# CC3200 register map
Vendor: Texas Instruments; File version: 1.0
CPU: CM4 r2p1, little endian, no MPU, no FPU, 3 interrupt priority bits
Registers are 32-bit, read-write, reset 0x0 unless marked. A register's access mark holds for its fields unless they carry their own. Offsets are from the block's base; [hi:lo] are bit positions; 'fields as' and 'values as' point back to an identical list.

## OCP_SHARED — MCU Shared Configuration
Base 0x4402E000
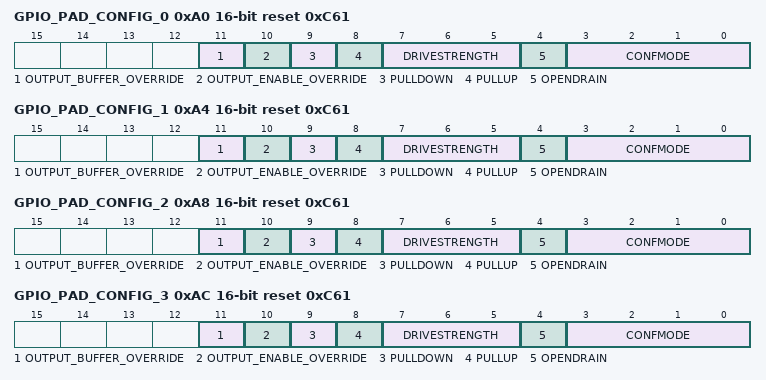
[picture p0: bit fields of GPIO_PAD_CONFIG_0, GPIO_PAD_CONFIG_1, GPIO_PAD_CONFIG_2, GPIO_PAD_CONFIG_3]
0xA0 GPIO_PAD_CONFIG_0 16-bit reset 0xC61 — GPIO0 / (ANA) (Pin 50) Pad Config
  [11] OUTPUT_BUFFER_OVERRIDE — Pad output buffer override enable
  [10] OUTPUT_ENABLE_OVERRIDE — Pad output enable override value
  [9] PULLDOWN — Enable internal weak pulldown
  [8] PULLUP — Enable internal weak pullup
  [7:5] DRIVESTRENGTH
    0=Disabled (Output driver not enabled); 1=2mA; 2=4mA; 3=6mA; 4=8mA; 5=10mA; 6=12mA; 7=14mA
  [4] OPENDRAIN — Open-drain Mode
  [3:0] CONFMODE — Configuration Mode
    0=GPIO0 (General-Purpose I/O); 3=UART0_RTS (UART0 Request To Send O (Active Low)); 4=McAXR0 (I2S Audio Port Data 0 (RX/TX)); 6=McAXR1 (I2S Audio Port Data 1 (RX/TX)); 7=GT_CCP00 (Timer Capture Port); 9=GSPI_CS (General SPI Chip Select); 10=UART1_RTS (UART1 Request To Send O (Active Low)); 12=UART0_CTS (UART0 Clear To Send Input (Active Low))
0xA4 GPIO_PAD_CONFIG_1 16-bit reset 0xC61 — GPIO1 (Pin 55) Pad Config
  [11] OUTPUT_BUFFER_OVERRIDE — Pad output buffer override enable
  [10] OUTPUT_ENABLE_OVERRIDE — Pad output enable override value
  [9] PULLDOWN — Enable internal weak pulldown
  [8] PULLUP — Enable internal weak pullup
  [7:5] DRIVESTRENGTH
    values as GPIO_PAD_CONFIG_0.DRIVESTRENGTH
  [4] OPENDRAIN — Open-drain Mode
  [3:0] CONFMODE — Configuration Mode
    0=GPIO1 (General-Purpose I/O); 3=UART0_TX (UART0 TX Data); 4=PIXCLK (Pixel Clock from Parallel Camera Sensor); 6=UART1_TX (UART1 TX Data); 7=GT_CCP01 (Timer Capture Port)
0xA8 GPIO_PAD_CONFIG_2 16-bit reset 0xC61 — GPIO2 (Pin 57) Pad Config
  [11] OUTPUT_BUFFER_OVERRIDE — Pad output buffer override enable
  [10] OUTPUT_ENABLE_OVERRIDE — Pad output enable override value
  [9] PULLDOWN — Enable internal weak pulldown
  [8] PULLUP — Enable internal weak pullup
  [7:5] DRIVESTRENGTH
    values as GPIO_PAD_CONFIG_0.DRIVESTRENGTH
  [4] OPENDRAIN — Open-drain Mode
  [3:0] CONFMODE — Configuration Mode
    0=GPIO2 (General-Purpose I/O); 3=UART0_RX (UART0 RX Data); 6=UART1_RX (UART1 RX Data); 7=GT_CCP02 (Timer Capture Port)
0xAC GPIO_PAD_CONFIG_3 16-bit reset 0xC61 — GPIO3 (Pin 58) Pad Config
  [11] OUTPUT_BUFFER_OVERRIDE — Pad output buffer override enable
  [10] OUTPUT_ENABLE_OVERRIDE — Pad output enable override value
  [9] PULLDOWN — Enable internal weak pulldown
  [8] PULLUP — Enable internal weak pullup
  [7:5] DRIVESTRENGTH
    values as GPIO_PAD_CONFIG_0.DRIVESTRENGTH
  [4] OPENDRAIN — Open-drain Mode
  [3:0] CONFMODE — Configuration Mode
    0=GPIO3 (General-Purpose I/O); 4=CAM_D3 (Parallel Camera Data Bit 3); 6=UART1_TX (UART1 TX Data)
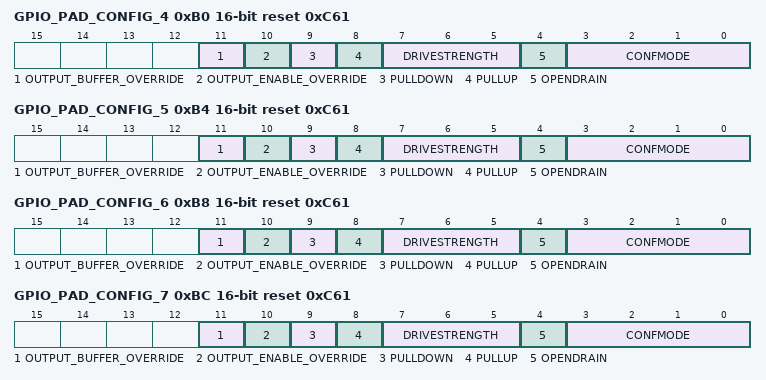
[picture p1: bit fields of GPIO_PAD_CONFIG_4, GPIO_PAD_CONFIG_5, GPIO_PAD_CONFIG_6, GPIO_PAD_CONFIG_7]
0xB0 GPIO_PAD_CONFIG_4 16-bit reset 0xC61 — GPIO4 (Pin 59) Pad Config
  [11] OUTPUT_BUFFER_OVERRIDE — Pad output buffer override enable
  [10] OUTPUT_ENABLE_OVERRIDE — Pad output enable override value
  [9] PULLDOWN — Enable internal weak pulldown
  [8] PULLUP — Enable internal weak pullup
  [7:5] DRIVESTRENGTH
    values as GPIO_PAD_CONFIG_0.DRIVESTRENGTH
  [4] OPENDRAIN — Open-drain Mode
  [3:0] CONFMODE — Configuration Mode
    0=GPIO4 (General-Purpose I/O); 4=CAM_D2 (Parallel Camera Data Bit 2); 6=UART1_RX (UART1 RX Data)
0xB4 GPIO_PAD_CONFIG_5 16-bit reset 0xC61 — GPIO5 (Pin 60) Pad Config
  [11] OUTPUT_BUFFER_OVERRIDE — Pad output buffer override enable
  [10] OUTPUT_ENABLE_OVERRIDE — Pad output enable override value
  [9] PULLDOWN — Enable internal weak pulldown
  [8] PULLUP — Enable internal weak pullup
  [7:5] DRIVESTRENGTH
    values as GPIO_PAD_CONFIG_0.DRIVESTRENGTH
  [4] OPENDRAIN — Open-drain Mode
  [3:0] CONFMODE — Configuration Mode
    0=GPIO5 (General-Purpose I/O); 4=CAM_D1 (Parallel Camera Data Bit 1); 6=McAXR1 (I2S Audio Port Data 1 (RX/TX)); 7=GT_CCP05 (Timer Capture Port)
0xB8 GPIO_PAD_CONFIG_6 16-bit reset 0xC61 — GPIO6 (Pin 61) Pad Config
  [11] OUTPUT_BUFFER_OVERRIDE — Pad output buffer override enable
  [10] OUTPUT_ENABLE_OVERRIDE — Pad output enable override value
  [9] PULLDOWN — Enable internal weak pulldown
  [8] PULLUP — Enable internal weak pullup
  [7:5] DRIVESTRENGTH
    values as GPIO_PAD_CONFIG_0.DRIVESTRENGTH
  [4] OPENDRAIN — Open-drain Mode
  [3:0] CONFMODE — Configuration Mode
    0=GPIO6 (General-Purpose I/O); 3=UART1_CTS (UART1 Clear To Send Input (Active Low)); 4=CAM_D0 (Parallel Camera Data Bit 0); 5=UART0_RTS (UART0 Request To Send O (Active Low)); 6=UART0_CTS (UART0 Clear To Send Input (Active Low)); 7=GT_CCP06 (Timer Capture Port)
0xBC GPIO_PAD_CONFIG_7 16-bit reset 0xC61 — GPIO7 (Pin 62) Pad Config
  [11] OUTPUT_BUFFER_OVERRIDE — Pad output buffer override enable
  [10] OUTPUT_ENABLE_OVERRIDE — Pad output enable override value
  [9] PULLDOWN — Enable internal weak pulldown
  [8] PULLUP — Enable internal weak pullup
  [7:5] DRIVESTRENGTH
    values as GPIO_PAD_CONFIG_0.DRIVESTRENGTH
  [4] OPENDRAIN — Open-drain Mode
  [3:0] CONFMODE — Configuration Mode
    0=GPIO7 (General-Purpose I/O); 3=UART1_RTS (UART1 Request To Send O (Active Low)); 10=UART0_RTS (UART0 Request To Send O (Active Low)); 11=UART0_TX (UART0 TX Data); 13=McACLKX (I2S Audio Port Clock O)
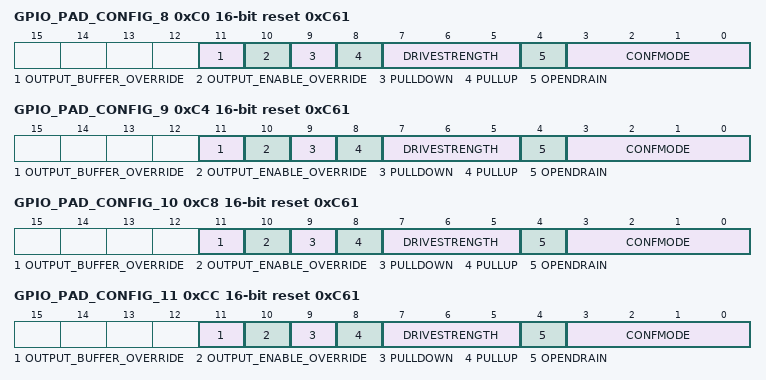
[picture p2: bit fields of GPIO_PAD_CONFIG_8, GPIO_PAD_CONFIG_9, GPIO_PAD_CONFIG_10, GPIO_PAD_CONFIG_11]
0xC0 GPIO_PAD_CONFIG_8 16-bit reset 0xC61 — GPIO8 (Pin 63) Pad Config
  [11] OUTPUT_BUFFER_OVERRIDE — Pad output buffer override enable
  [10] OUTPUT_ENABLE_OVERRIDE — Pad output enable override value
  [9] PULLDOWN — Enable internal weak pulldown
  [8] PULLUP — Enable internal weak pullup
  [7:5] DRIVESTRENGTH
    values as GPIO_PAD_CONFIG_0.DRIVESTRENGTH
  [4] OPENDRAIN — Open-drain Mode
  [3:0] CONFMODE — Configuration Mode
    0=GPIO8 (General-Purpose I/O); 6=SDCARD_IRQ (Interrupt from SD Card); 7=McAFSX (I2S Audio Port Frame Sync); 12=GT_CCP06 (Timer Capture Port)
0xC4 GPIO_PAD_CONFIG_9 16-bit reset 0xC61 — GPIO9 (Pin 64) Pad Config
  [11] OUTPUT_BUFFER_OVERRIDE — Pad output buffer override enable
  [10] OUTPUT_ENABLE_OVERRIDE — Pad output enable override value
  [9] PULLDOWN — Enable internal weak pulldown
  [8] PULLUP — Enable internal weak pullup
  [7:5] DRIVESTRENGTH
    values as GPIO_PAD_CONFIG_0.DRIVESTRENGTH
  [4] OPENDRAIN — Open-drain Mode
  [3:0] CONFMODE — Configuration Mode
    0=GPIO9 (General-Purpose I/O); 3=GT_PWM05 (Pulse-Width Modulated O/P); 6=SDCARD_DATA; 7=McAXR0 (I2S Audio Port Data (Rx/Tx)); 12=GT_CCP00 (Timer Capture Port)
0xC8 GPIO_PAD_CONFIG_10 16-bit reset 0xC61 — GPIO10 (Pin 1) Pad Config
  [11] OUTPUT_BUFFER_OVERRIDE — Pad output buffer override enable
  [10] OUTPUT_ENABLE_OVERRIDE — Pad output enable override value
  [9] PULLDOWN — Enable internal weak pulldown
  [8] PULLUP — Enable internal weak pullup
  [7:5] DRIVESTRENGTH
    values as GPIO_PAD_CONFIG_0.DRIVESTRENGTH
  [4] OPENDRAIN — Open-drain Mode
  [3:0] CONFMODE — Configuration Mode
    0=GPIO10 (General-Purpose I/O); 1=I2C_SCL (I2C Clock); 3=GT_PWM06 (Pulse-Width Modulated O/P); 6=SDCARD_CLK (SD Card Clock); 7=UART1_TX (UART1 TX Data); 12=GT_CCP01 (Timer Capture Port)
0xCC GPIO_PAD_CONFIG_11 16-bit reset 0xC61 — GPIO11 (Pin 2) Pad Config
  [11] OUTPUT_BUFFER_OVERRIDE — Pad output buffer override enable
  [10] OUTPUT_ENABLE_OVERRIDE — Pad output enable override value
  [9] PULLDOWN — Enable internal weak pulldown
  [8] PULLUP — Enable internal weak pullup
  [7:5] DRIVESTRENGTH
    values as GPIO_PAD_CONFIG_0.DRIVESTRENGTH
  [4] OPENDRAIN — Open-drain Mode
  [3:0] CONFMODE — Configuration Mode
    0=GPIO11 (General-Purpose I/O); 1=I2C_SDA (I2C Data); 3=GT_PWM07 (Pulse-Width Modulated O/P); 4=XVCLK (Free Clock To Parallel Camera); 6=SDCARD_CMD (SD Card Command Line); 7=UART1_RX (UART1 RX Data); 12=GT_CCP02 (Timer Capture Port); 13=McAFSX (I2S Audio Port Frame Sync)
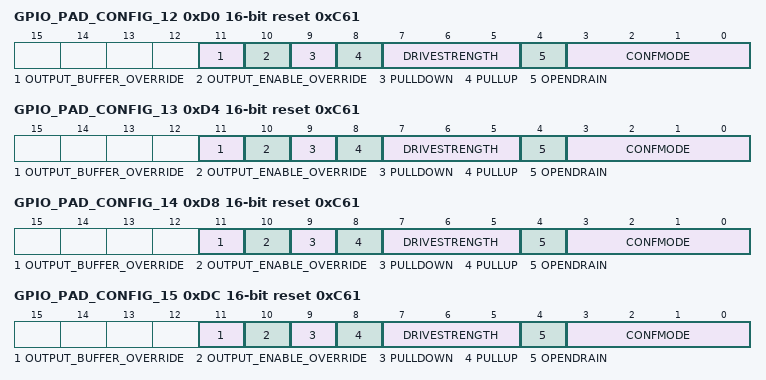
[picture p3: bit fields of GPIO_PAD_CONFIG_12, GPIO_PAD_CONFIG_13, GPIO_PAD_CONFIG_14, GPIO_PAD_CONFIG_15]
0xD0 GPIO_PAD_CONFIG_12 16-bit reset 0xC61 — GPIO12 (Pin 3) Pad Config
  [11] OUTPUT_BUFFER_OVERRIDE — Pad output buffer override enable
  [10] OUTPUT_ENABLE_OVERRIDE — Pad output enable override value
  [9] PULLDOWN — Enable internal weak pulldown
  [8] PULLUP — Enable internal weak pullup
  [7:5] DRIVESTRENGTH
    values as GPIO_PAD_CONFIG_0.DRIVESTRENGTH
  [4] OPENDRAIN — Open-drain Mode
  [3:0] CONFMODE — Configuration Mode
    0=GPIO12 (General-Purpose I/O); 3=McACLK (I2S Audio Port Clock O); 4=VSYNC (Parallel Camera Vertical Sync); 5=I2C_SCL (I2C Clock); 7=UART0_TX (UART0 TX Data); 12=GT_CCP03 (Timer Capture Port)
0xD4 GPIO_PAD_CONFIG_13 16-bit reset 0xC61 — GPIO13 (Pin 4) Pad Config
  [11] OUTPUT_BUFFER_OVERRIDE — Pad output buffer override enable
  [10] OUTPUT_ENABLE_OVERRIDE — Pad output enable override value
  [9] PULLDOWN — Enable internal weak pulldown
  [8] PULLUP — Enable internal weak pullup
  [7:5] DRIVESTRENGTH
    values as GPIO_PAD_CONFIG_0.DRIVESTRENGTH
  [4] OPENDRAIN — Open-drain Mode
  [3:0] CONFMODE — Configuration Mode
    0=GPIO13 (General-Purpose I/O); 4=HSYNC (Parallel Camera Horizontal Sync); 5=I2C_SDA (I2C Data); 7=UART0_RX (UART0 RX Data); 12=GT_CCP04 (Timer Capture Port)
0xD8 GPIO_PAD_CONFIG_14 16-bit reset 0xC61 — GPIO14 (Pin 5) Pad Config
  [11] OUTPUT_BUFFER_OVERRIDE — Pad output buffer override enable
  [10] OUTPUT_ENABLE_OVERRIDE — Pad output enable override value
  [9] PULLDOWN — Enable internal weak pulldown
  [8] PULLUP — Enable internal weak pullup
  [7:5] DRIVESTRENGTH
    values as GPIO_PAD_CONFIG_0.DRIVESTRENGTH
  [4] OPENDRAIN — Open-drain Mode
  [3:0] CONFMODE — Configuration Mode
    0=GPIO14 (General-Purpose I/O); 4=CAM_D4 (Parallel Camera Data Bit 4); 5=I2C_SCL (I2C Clock); 7=GSPI_CLK (General SPI Clock); 12=GT_CCP05 (Timer Capture Port)
0xDC GPIO_PAD_CONFIG_15 16-bit reset 0xC61 — GPIO15 (Pin 6) Pad Config
  [11] OUTPUT_BUFFER_OVERRIDE — Pad output buffer override enable
  [10] OUTPUT_ENABLE_OVERRIDE — Pad output enable override value
  [9] PULLDOWN — Enable internal weak pulldown
  [8] PULLUP — Enable internal weak pullup
  [7:5] DRIVESTRENGTH
    values as GPIO_PAD_CONFIG_0.DRIVESTRENGTH
  [4] OPENDRAIN — Open-drain Mode
  [3:0] CONFMODE — Configuration Mode
    0=GPIO15 (General-Purpose I/O); 4=CAM_D5 (Parallel Camera Data Bit 5); 5=I2C_SDA (I2C Data); 7=GSPI_MISO (General SPI MISO); 8=SDCARD_DATA; 13=GT_CCP06 (Timer Capture Port)
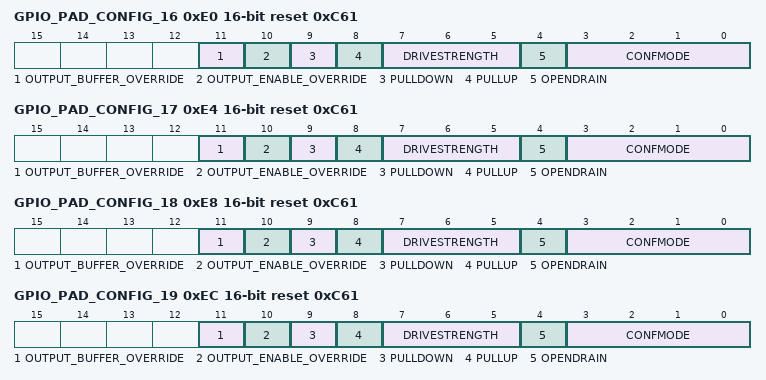
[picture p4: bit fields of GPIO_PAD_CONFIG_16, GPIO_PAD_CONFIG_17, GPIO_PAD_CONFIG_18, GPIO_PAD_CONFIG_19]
0xE0 GPIO_PAD_CONFIG_16 16-bit reset 0xC61 — GPIO16 (Pin 7) Pad Config
  [11] OUTPUT_BUFFER_OVERRIDE — Pad output buffer override enable
  [10] OUTPUT_ENABLE_OVERRIDE — Pad output enable override value
  [9] PULLDOWN — Enable internal weak pulldown
  [8] PULLUP — Enable internal weak pullup
  [7:5] DRIVESTRENGTH
    values as GPIO_PAD_CONFIG_0.DRIVESTRENGTH
  [4] OPENDRAIN — Open-drain Mode
  [3:0] CONFMODE — Configuration Mode
    0=GPIO16 (General-Purpose I/O); 4=CAM_D6 (Parallel Camera Data Bit 6); 5=UART1_TX (UART1 TX Data); 7=GSPI_MOSI (General SPI MOSI); 8=SDCARD_CLK (SD Card Clock); 13=GT_CCP07 (Timer Capture Port)
0xE4 GPIO_PAD_CONFIG_17 16-bit reset 0xC61 — GPIO17 (Pin 8) Pad Config
  [11] OUTPUT_BUFFER_OVERRIDE — Pad output buffer override enable
  [10] OUTPUT_ENABLE_OVERRIDE — Pad output enable override value
  [9] PULLDOWN — Enable internal weak pulldown
  [8] PULLUP — Enable internal weak pullup
  [7:5] DRIVESTRENGTH
    values as GPIO_PAD_CONFIG_0.DRIVESTRENGTH
  [4] OPENDRAIN — Open-drain Mode
  [3:0] CONFMODE — Configuration Mode
    0=GPIO17 (General-Purpose I/O); 4=CAM_D7 (Parallel Camera Data Bit 7); 5=UART1_RX (UART1 RX Data); 7=GSPI_CS (General SPI Chip Select); 8=SDCARD_CMD (SD Card Command Line)
0xE8 GPIO_PAD_CONFIG_18 16-bit reset 0xC61 — GPIO18 (SPI_FLASH_CLK) (Pin 11) Pad Config
  [11] OUTPUT_BUFFER_OVERRIDE — Pad output buffer override enable
  [10] OUTPUT_ENABLE_OVERRIDE — Pad output enable override value
  [9] PULLDOWN — Enable internal weak pulldown
  [8] PULLUP — Enable internal weak pullup
  [7:5] DRIVESTRENGTH
    values as GPIO_PAD_CONFIG_0.DRIVESTRENGTH
  [4] OPENDRAIN — Open-drain Mode
  [3:0] CONFMODE — Configuration Mode
    1=FLASH_SPI_CLK (Clock To SPI Serial Flash (Fixed Default))
0xEC GPIO_PAD_CONFIG_19 16-bit reset 0xC61 — GPIO19 (SPI_FLASH_DOUT) (Pin 12) Pad Config
  [11] OUTPUT_BUFFER_OVERRIDE — Pad output buffer override enable
  [10] OUTPUT_ENABLE_OVERRIDE — Pad output enable override value
  [9] PULLDOWN — Enable internal weak pulldown
  [8] PULLUP — Enable internal weak pullup
  [7:5] DRIVESTRENGTH
    values as GPIO_PAD_CONFIG_0.DRIVESTRENGTH
  [4] OPENDRAIN — Open-drain Mode
  [3:0] CONFMODE — Configuration Mode
    1=FLASH_SPI_DOUT (Data To SPI Serial Flash (Fixed Default))
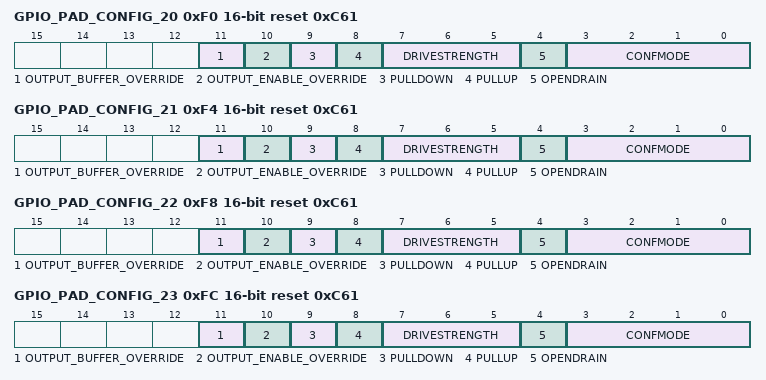
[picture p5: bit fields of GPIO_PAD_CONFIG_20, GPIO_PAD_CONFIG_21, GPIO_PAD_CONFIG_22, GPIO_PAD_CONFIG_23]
0xF0 GPIO_PAD_CONFIG_20 16-bit reset 0xC61 — GPIO20 (SPI_FLASH_DIN) (Pin 13) Pad Config
  [11] OUTPUT_BUFFER_OVERRIDE — Pad output buffer override enable
  [10] OUTPUT_ENABLE_OVERRIDE — Pad output enable override value
  [9] PULLDOWN — Enable internal weak pulldown
  [8] PULLUP — Enable internal weak pullup
  [7:5] DRIVESTRENGTH
    values as GPIO_PAD_CONFIG_0.DRIVESTRENGTH
  [4] OPENDRAIN — Open-drain Mode
  [3:0] CONFMODE — Configuration Mode
    1=FLASH_SPI_DIN (Data From SPI Serial Flash (Fixed Default))
0xF4 GPIO_PAD_CONFIG_21 16-bit reset 0xC61 — GPIO21 (SPI_FLASH_CS) (Pin 14) Pad Config
  [11] OUTPUT_BUFFER_OVERRIDE — Pad output buffer override enable
  [10] OUTPUT_ENABLE_OVERRIDE — Pad output enable override value
  [9] PULLDOWN — Enable internal weak pulldown
  [8] PULLUP — Enable internal weak pullup
  [7:5] DRIVESTRENGTH
    values as GPIO_PAD_CONFIG_0.DRIVESTRENGTH
  [4] OPENDRAIN — Open-drain Mode
  [3:0] CONFMODE — Configuration Mode
    1=SPI_FLASH_CS (Chip Select To SPI Serial Flash (Fixed Default))
0xF8 GPIO_PAD_CONFIG_22 16-bit reset 0xC61 — GPIO22 (Pin 15) Pad Config
  [11] OUTPUT_BUFFER_OVERRIDE — Pad output buffer override enable
  [10] OUTPUT_ENABLE_OVERRIDE — Pad output enable override value
  [9] PULLDOWN — Enable internal weak pulldown
  [8] PULLUP — Enable internal weak pullup
  [7:5] DRIVESTRENGTH
    values as GPIO_PAD_CONFIG_0.DRIVESTRENGTH
  [4] OPENDRAIN — Open-drain Mode
  [3:0] CONFMODE — Configuration Mode
    0=GPIO22 (General-Purpose I/O); 5=GT_CCP04 (Timer Capture Port); 7=McAFSX (I2S Audio Port Frame Sync)
0xFC GPIO_PAD_CONFIG_23 16-bit reset 0xC61 — GPIO23 (TDI) (Pin 16) Pad Config
  [11] OUTPUT_BUFFER_OVERRIDE — Pad output buffer override enable
  [10] OUTPUT_ENABLE_OVERRIDE — Pad output enable override value
  [9] PULLDOWN — Enable internal weak pulldown
  [8] PULLUP — Enable internal weak pullup
  [7:5] DRIVESTRENGTH
    values as GPIO_PAD_CONFIG_0.DRIVESTRENGTH
  [4] OPENDRAIN — Open-drain Mode
  [3:0] CONFMODE — Configuration Mode
    0=GPIO23 (General-Purpose I/O); 1=TDI (JTAG TDI (Reset Default Pinout)); 2=UART1_TX (UART1 TX Data); 9=I2C_SCL (I2C Clock)
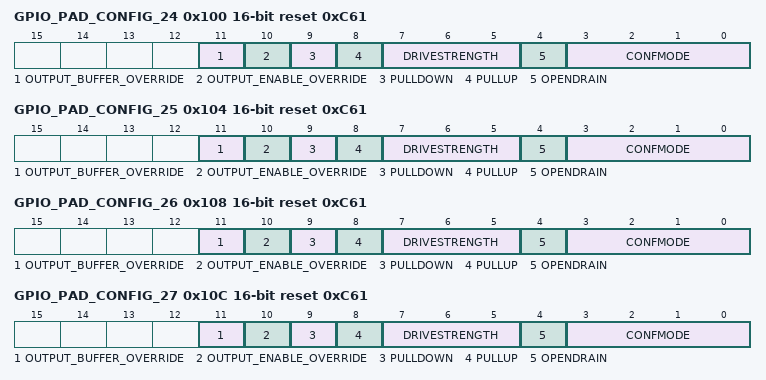
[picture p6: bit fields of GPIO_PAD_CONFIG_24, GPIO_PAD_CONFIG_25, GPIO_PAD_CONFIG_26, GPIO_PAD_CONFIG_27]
0x100 GPIO_PAD_CONFIG_24 16-bit reset 0xC61 — GPIO24 (TDO) (Pin 17) Pad Config
  [11] OUTPUT_BUFFER_OVERRIDE — Pad output buffer override enable
  [10] OUTPUT_ENABLE_OVERRIDE — Pad output enable override value
  [9] PULLDOWN — Enable internal weak pulldown
  [8] PULLUP — Enable internal weak pullup
  [7:5] DRIVESTRENGTH
    values as GPIO_PAD_CONFIG_0.DRIVESTRENGTH
  [4] OPENDRAIN — Open-drain Mode
  [3:0] CONFMODE — Configuration Mode
    0=GPIO24 (General-Purpose I/O); 1=TDO (JTAG TDO (Reset Default Pinout)); 2=UART1_RX (UART1 RX Data); 4=GT_CCP06 (Timer Capture Port); 5=PWM0 (Pulse-Width Modulated O/P); 6=McAFSX (I2S Audio Port Frame Sync); 9=I2C_SDA (I2C Data)
0x104 GPIO_PAD_CONFIG_25 16-bit reset 0xC61 — GPIO25 (SOP2) (Pin 21) Pad Config
  [11] OUTPUT_BUFFER_OVERRIDE — Pad output buffer override enable
  [10] OUTPUT_ENABLE_OVERRIDE — Pad output enable override value
  [9] PULLDOWN — Enable internal weak pulldown
  [8] PULLUP — Enable internal weak pullup
  [7:5] DRIVESTRENGTH
    values as GPIO_PAD_CONFIG_0.DRIVESTRENGTH
  [4] OPENDRAIN — Open-drain Mode
  [3:0] CONFMODE — Configuration Mode
    0=GPIO25 (General-Purpose I/O); 2=McAFSX (I2S Audio Port Frame Sync); 9=GT_PWM02 (Pulse-Width Modulated O/P)
0x108 GPIO_PAD_CONFIG_26 16-bit reset 0xC61 — GPIO26 (ANTSEL1) (Pin 29) Pad Config
  [11] OUTPUT_BUFFER_OVERRIDE — Pad output buffer override enable
  [10] OUTPUT_ENABLE_OVERRIDE — Pad output enable override value
  [9] PULLDOWN — Enable internal weak pulldown
  [8] PULLUP — Enable internal weak pullup
  [7:5] DRIVESTRENGTH
    values as GPIO_PAD_CONFIG_0.DRIVESTRENGTH
  [4] OPENDRAIN — Open-drain Mode
  [3:0] CONFMODE — Configuration Mode
    0=ANTSEL1 (Antenna Selection Control)
0x10C GPIO_PAD_CONFIG_27 16-bit reset 0xC61 — GPIO27 (ANTSEL2) (Pin 30) Pad Config
  [11] OUTPUT_BUFFER_OVERRIDE — Pad output buffer override enable
  [10] OUTPUT_ENABLE_OVERRIDE — Pad output enable override value
  [9] PULLDOWN — Enable internal weak pulldown
  [8] PULLUP — Enable internal weak pullup
  [7:5] DRIVESTRENGTH
    values as GPIO_PAD_CONFIG_0.DRIVESTRENGTH
  [4] OPENDRAIN — Open-drain Mode
  [3:0] CONFMODE — Configuration Mode
    0=ANTSEL2 (Antenna Selection Control)
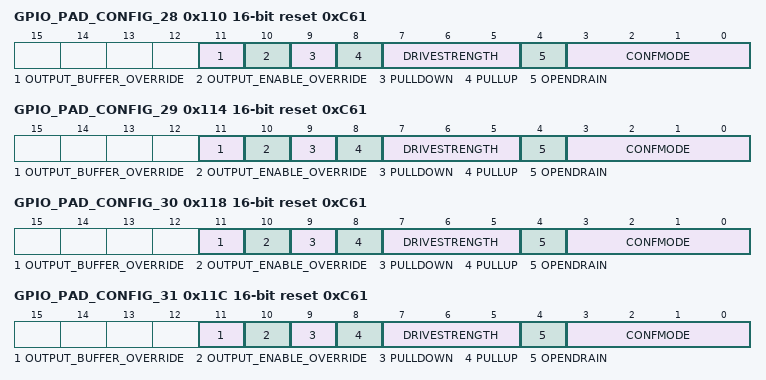
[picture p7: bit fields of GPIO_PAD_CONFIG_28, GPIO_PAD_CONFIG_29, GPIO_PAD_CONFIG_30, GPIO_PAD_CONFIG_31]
0x110 GPIO_PAD_CONFIG_28 16-bit reset 0xC61 — GPIO28 (TCK) (Pin 19) Pad Config
  [11] OUTPUT_BUFFER_OVERRIDE — Pad output buffer override enable
  [10] OUTPUT_ENABLE_OVERRIDE — Pad output enable override value
  [9] PULLDOWN — Enable internal weak pulldown
  [8] PULLUP — Enable internal weak pullup
  [7:5] DRIVESTRENGTH
    values as GPIO_PAD_CONFIG_0.DRIVESTRENGTH
  [4] OPENDRAIN — Open-drain Mode
  [3:0] CONFMODE — Configuration Mode
    0=GPIO28 (General-Purpose I/O); 1=TCK (JTAG/SWD TCK (Reset Default Pinout)); 8=GT_PWM03 (Pulse-Width Modulated O/P)
0x114 GPIO_PAD_CONFIG_29 16-bit reset 0xC61 — GPIO29 (TMS) (Pin 20) Pad Config
  [11] OUTPUT_BUFFER_OVERRIDE — Pad output buffer override enable
  [10] OUTPUT_ENABLE_OVERRIDE — Pad output enable override value
  [9] PULLDOWN — Enable internal weak pulldown
  [8] PULLUP — Enable internal weak pullup
  [7:5] DRIVESTRENGTH
    values as GPIO_PAD_CONFIG_0.DRIVESTRENGTH
  [4] OPENDRAIN — Open-drain Mode
  [3:0] CONFMODE — Configuration Mode
    0=GPIO29 (General-Purpose I/O); 1=TMS (JTAG/SWD TMS (Reset Default Pinout))
0x118 GPIO_PAD_CONFIG_30 16-bit reset 0xC61 — GPIO30 (ANA) (Pin 53) Pad Config
  [11] OUTPUT_BUFFER_OVERRIDE — Pad output buffer override enable
  [10] OUTPUT_ENABLE_OVERRIDE — Pad output enable override value
  [9] PULLDOWN — Enable internal weak pulldown
  [8] PULLUP — Enable internal weak pullup
  [7:5] DRIVESTRENGTH
    values as GPIO_PAD_CONFIG_0.DRIVESTRENGTH
  [4] OPENDRAIN — Open-drain Mode
  [3:0] CONFMODE — Configuration Mode
    0=GPIO30 (General-Purpose I/O); 2=McACLK (I2S Audio Port Clock O); 3=McAFSX (I2S Audio Port Frame Sync); 4=GT_CCP05 (Timer Capture Port); 7=GSPI_MISO (General SPI MISO); 9=UART0_TX (UART0 TX Data)
0x11C GPIO_PAD_CONFIG_31 16-bit reset 0xC61 — GPIO31 (DCDC_ANA2_SW_P) (Pin 45) Pad Config
  [11] OUTPUT_BUFFER_OVERRIDE — Pad output buffer override enable
  [10] OUTPUT_ENABLE_OVERRIDE — Pad output enable override value
  [9] PULLDOWN — Enable internal weak pulldown
  [8] PULLUP — Enable internal weak pullup
  [7:5] DRIVESTRENGTH
    values as GPIO_PAD_CONFIG_0.DRIVESTRENGTH
  [4] OPENDRAIN — Open-drain Mode
  [3:0] CONFMODE — Configuration Mode
    0=GPIO31 (General-Purpose I/O); 2=UART1_RX (UART1 RX Data); 6=McAXR0 (I2S Audio Port Data 0 (RX/TX)); 7=GSPI_CLK (General SPI Clock); 9=UART0_RX (UART0 RX Data); 12=McAFSX (I2S Audio Port Frame Sync)
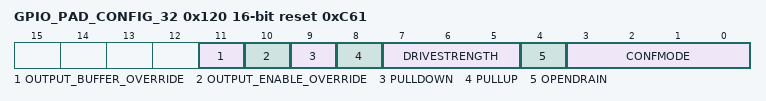
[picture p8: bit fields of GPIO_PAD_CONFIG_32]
0x120 GPIO_PAD_CONFIG_32 16-bit reset 0xC61 — GPIO32 (RTC_XTAL_N) (Pin 52) Pad Config
  [11] OUTPUT_BUFFER_OVERRIDE — Pad output buffer override enable
  [10] OUTPUT_ENABLE_OVERRIDE — Pad output enable override value
  [9] PULLDOWN — Enable internal weak pulldown
  [8] PULLUP — Enable internal weak pullup
  [7:5] DRIVESTRENGTH
    values as GPIO_PAD_CONFIG_0.DRIVESTRENGTH
  [4] OPENDRAIN — Open-drain Mode
  [3:0] CONFMODE — Configuration Mode
    0=GPIO32 (General-Purpose I/O); 1=RTC_XTAL_N (Connect 32.768kHz XTAL or connect a 100kΩ to Vsupply); 2=McACLK (I2S Audio Port Clock O); 4=McAXR0 (I2S Audio Port Data (Only O Mode Supported On Pin 52)); 6=UART0_RTS (UART0 Request To Send O (Active Low)); 8=GSPI_MOSI (General SPI MOSI)
